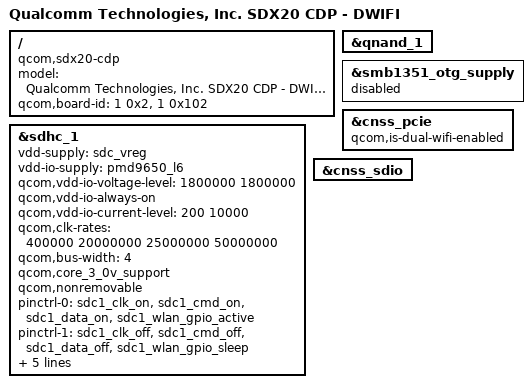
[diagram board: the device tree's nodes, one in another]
/* Copyright (c) 2017, The Linux Foundation. All rights reserved.
 *
 * This program is free software; you can redistribute it and/or modify
 * it under the terms of the GNU General Public License version 2 and
 * only version 2 as published by the Free Software Foundation.
 *
 * This program is distributed in the hope that it will be useful,
 * but WITHOUT ANY WARRANTY; without even the implied warranty of
 * MERCHANTABILITY or FITNESS FOR A PARTICULAR PURPOSE.  See the
 * GNU General Public License for more details.
 */

/dts-v1/;

#include "sdx20-cdp.dtsi"

/ {
	model = "Qualcomm Technologies, Inc. SDX20 CDP - DWIFI";
	compatible = "qcom,sdx20-cdp", "qcom,sdx20",
		     "qcom,cdp";
	qcom,board-id = <1 0x2>, <1 0x102>;
};

&qnand_1 {
	status = "ok";
};

&smb1351_otg_supply {
	status = "disabled";
};

&sdhc_1 {
	vdd-supply = <&sdc_vreg>;
	vdd-io-supply = <&pmd9650_l6>;
	qcom,vdd-io-voltage-level = <1800000 1800000>;
	qcom,vdd-io-always-on;
	qcom,vdd-io-current-level = <200 10000>;

	qcom,clk-rates = <400000 20000000 25000000 50000000>;
	qcom,bus-width = <4>;
	qcom,core_3_0v_support;
	qcom,nonremovable;

	pinctrl-names = "active", "sleep";
	pinctrl-0 = <&sdc1_clk_on &sdc1_cmd_on &sdc1_data_on
				&sdc1_wlan_gpio_active>;
	pinctrl-1 = <&sdc1_clk_off &sdc1_cmd_off &sdc1_data_off
				&sdc1_wlan_gpio_sleep>;
	#address-cells = <0>;
	interrupt-parent = <&sdhc_1>;
	interrupts = <0 1 2>;
	#interrupt-cells = <1>;
	interrupt-map-mask = <0xffffffff>;
	interrupt-map = <0 &intc 0 123 0
			1 &intc 0 138 0
			2 &tlmm_pinmux 81 0x4>;
	interrupt-names = "hc_irq", "pwr_irq", "sdiowakeup_irq";

	status = "ok";
};

&cnss_pcie {
	qcom,is-dual-wifi-enabled;
};

&cnss_sdio {
	status = "ok";
};
